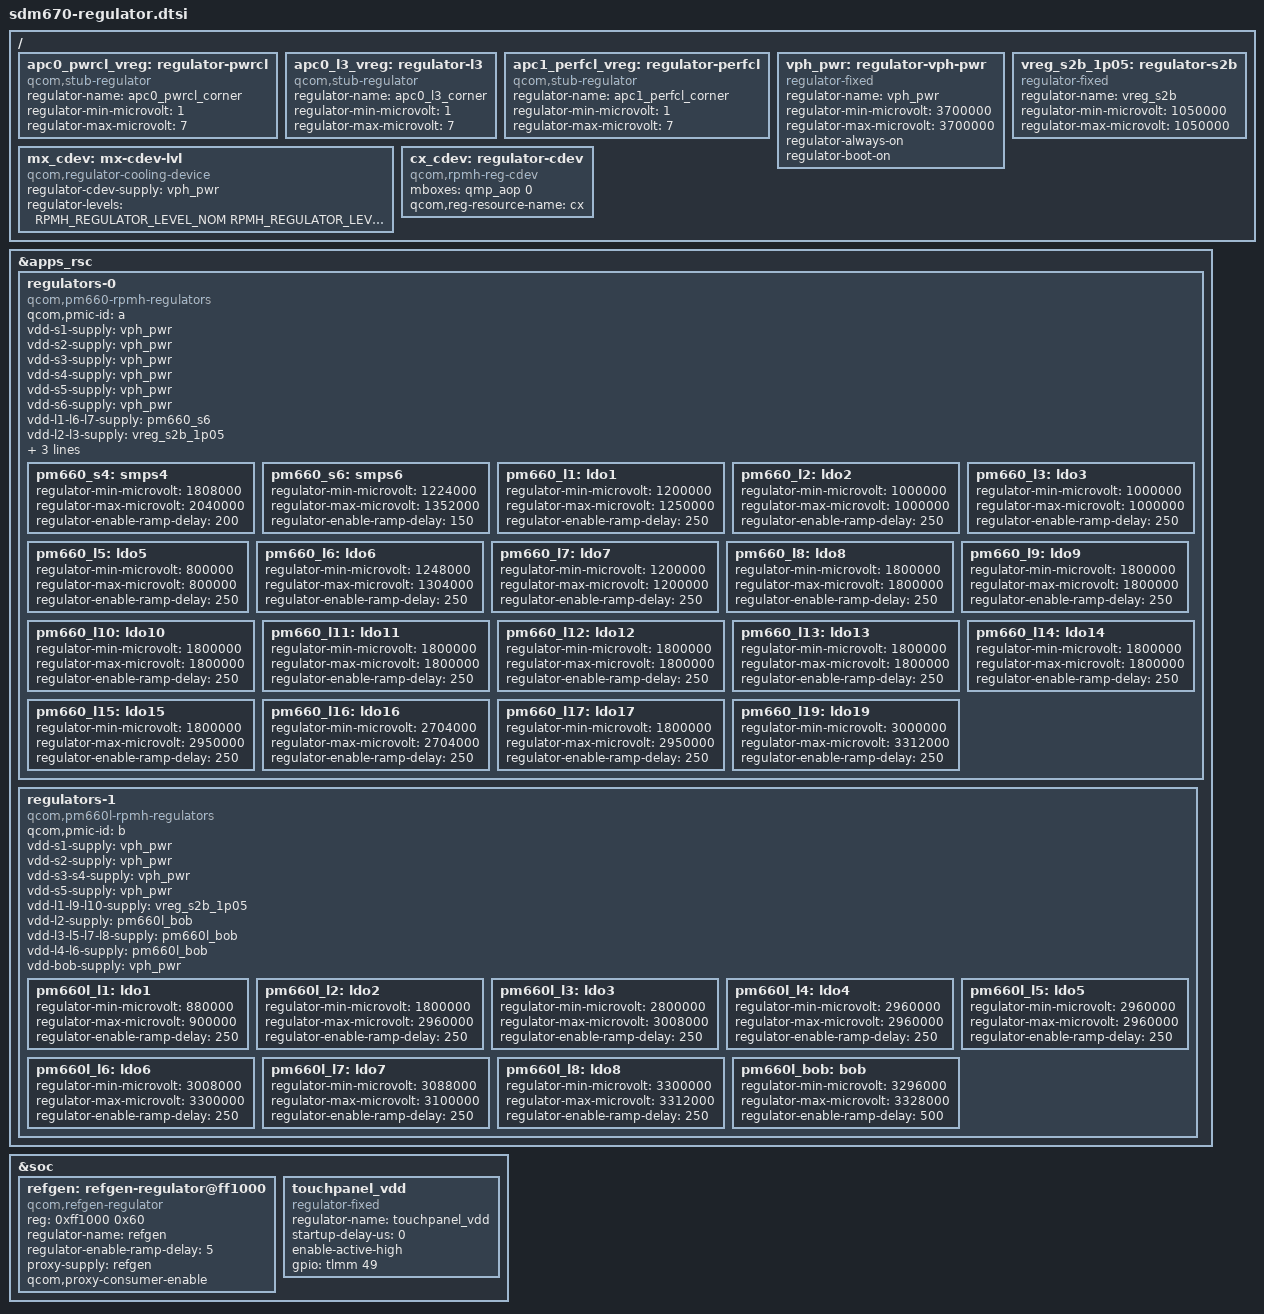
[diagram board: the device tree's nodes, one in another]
/* Copyright (c) 2017,2020 The Linux Foundation. All rights reserved.
 * PBEM00 port: converted from the CLO rpmh-regulator binding (mboxes +
 * qcom,resource-name + ARC level regulators) to the mainline binding
 * (qcom,pm660{,l}-rpmh-regulators under apps_rsc + rpmhpd for ARC rails).
 * All consumer-facing labels (pm660_*, pm660l_*, mx_cdev, cx_cdev) are
 * preserved so the stock dtbo overlay keeps resolving. */

#include <dt-bindings/regulator/qcom,rpmh-regulator.h>

/* Stub regulators */

/ {
	apc0_pwrcl_vreg: regulator-pwrcl {
		compatible = "qcom,stub-regulator";
		regulator-name = "apc0_pwrcl_corner";
		regulator-min-microvolt = <1>;
		regulator-max-microvolt = <7>;
	};

	apc0_l3_vreg: regulator-l3 {
		compatible = "qcom,stub-regulator";
		regulator-name = "apc0_l3_corner";
		regulator-min-microvolt = <1>;
		regulator-max-microvolt = <7>;
	};

	apc1_perfcl_vreg: regulator-perfcl {
		compatible = "qcom,stub-regulator";
		regulator-name = "apc1_perfcl_corner";
		regulator-min-microvolt = <1>;
		regulator-max-microvolt = <7>;
	};

	/* Battery rail feeding the SMPS inputs (cf. sdm670-google-common) */
	vph_pwr: regulator-vph-pwr {
		compatible = "regulator-fixed";
		regulator-name = "vph_pwr";
		regulator-min-microvolt = <3700000>;
		regulator-max-microvolt = <3700000>;
		regulator-always-on;
		regulator-boot-on;
	};

	/* pm660l S2 feed for LDOs (downstream models it as an ARC-only rail;
	 * fixed-voltage placeholder per sdm670-google-common) */
	vreg_s2b_1p05: regulator-s2b {
		compatible = "regulator-fixed";
		regulator-name = "vreg_s2b";
		regulator-min-microvolt = <1050000>;
		regulator-max-microvolt = <1050000>;
	};

	/* Cooling devices (kept label-compatible with sdm670-thermal.dtsi;
	 * the CLO cooling drivers are not present in mainline, so these
	 * merely keep the phandles resolvable) */
	mx_cdev: mx-cdev-lvl {
		compatible = "qcom,regulator-cooling-device";
		regulator-cdev-supply = <&vph_pwr>;
		regulator-levels = <RPMH_REGULATOR_LEVEL_NOM
				RPMH_REGULATOR_LEVEL_OFF>;
		#cooling-cells = <2>;
	};

	cx_cdev: regulator-cdev {
		compatible = "qcom,rpmh-reg-cdev";
		mboxes = <&qmp_aop 0>;
		qcom,reg-resource-name = "cx";
		#cooling-cells = <2>;
	};
};

&apps_rsc {
	regulators-0 {
		compatible = "qcom,pm660-rpmh-regulators";
		qcom,pmic-id = "a";

		vdd-s1-supply = <&vph_pwr>;
		vdd-s2-supply = <&vph_pwr>;
		vdd-s3-supply = <&vph_pwr>;
		vdd-s4-supply = <&vph_pwr>;
		vdd-s5-supply = <&vph_pwr>;
		vdd-s6-supply = <&vph_pwr>;

		vdd-l1-l6-l7-supply = <&pm660_s6>;
		vdd-l2-l3-supply = <&vreg_s2b_1p05>;
		vdd-l5-supply = <&vreg_s2b_1p05>;
		vdd-l8-l9-l10-l11-l12-l13-l14-supply = <&pm660_s4>;
		vdd-l15-l16-l17-l18-l19-supply = <&pm660l_bob>;

		pm660_s4: smps4 {
			regulator-min-microvolt = <1808000>;
			regulator-max-microvolt = <2040000>;
			regulator-enable-ramp-delay = <200>;
		};

		pm660_s6: smps6 {
			regulator-min-microvolt = <1224000>;
			regulator-max-microvolt = <1352000>;
			regulator-enable-ramp-delay = <150>;
		};

		/* LDOs (voltages carried over from the CLO rail table) */
		pm660_l1: ldo1 {
			regulator-min-microvolt = <1200000>;
			regulator-max-microvolt = <1250000>;
			regulator-enable-ramp-delay = <250>;
		};

		pm660_l2: ldo2 {
			regulator-min-microvolt = <1000000>;
			regulator-max-microvolt = <1000000>;
			regulator-enable-ramp-delay = <250>;
		};

		pm660_l3: ldo3 {
			regulator-min-microvolt = <1000000>;
			regulator-max-microvolt = <1000000>;
			regulator-enable-ramp-delay = <250>;
		};

		pm660_l5: ldo5 {
			regulator-min-microvolt = <800000>;
			regulator-max-microvolt = <800000>;
			regulator-enable-ramp-delay = <250>;
		};

		pm660_l6: ldo6 {
			regulator-min-microvolt = <1248000>;
			regulator-max-microvolt = <1304000>;
			regulator-enable-ramp-delay = <250>;
		};

		pm660_l7: ldo7 {
			regulator-min-microvolt = <1200000>;
			regulator-max-microvolt = <1200000>;
			regulator-enable-ramp-delay = <250>;
		};

		pm660_l8: ldo8 {
			regulator-min-microvolt = <1800000>;
			regulator-max-microvolt = <1800000>;
			regulator-enable-ramp-delay = <250>;
		};

		pm660_l9: ldo9 {
			regulator-min-microvolt = <1800000>;
			regulator-max-microvolt = <1800000>;
			regulator-enable-ramp-delay = <250>;
		};

		pm660_l10: ldo10 {
			regulator-min-microvolt = <1800000>;
			regulator-max-microvolt = <1800000>;
			regulator-enable-ramp-delay = <250>;
		};

		pm660_l11: ldo11 {
			regulator-min-microvolt = <1800000>;
			regulator-max-microvolt = <1800000>;
			regulator-enable-ramp-delay = <250>;
		};

		pm660_l12: ldo12 {
			regulator-min-microvolt = <1800000>;
			regulator-max-microvolt = <1800000>;
			regulator-enable-ramp-delay = <250>;
		};

		pm660_l13: ldo13 {
			regulator-min-microvolt = <1800000>;
			regulator-max-microvolt = <1800000>;
			regulator-enable-ramp-delay = <250>;
		};

		pm660_l14: ldo14 {
			regulator-min-microvolt = <1800000>;
			regulator-max-microvolt = <1800000>;
			regulator-enable-ramp-delay = <250>;
		};

		pm660_l15: ldo15 {
			regulator-min-microvolt = <1800000>;
			regulator-max-microvolt = <2950000>;
			regulator-enable-ramp-delay = <250>;
		};

		/* Stock fixes L16 at 2700000; CLO sends raw uV for the firmware to
		 * round, but 2700000 rides between the 8000 uV PMIC4 PLDO steps
		 * (2696000/2704000) and the strict upstream selector mapping
		 * rejects it at register time with -EINVAL, failing the whole
		 * regulators-0 probe. Snap to the ceiling step. */
		pm660_l16: ldo16 {
			regulator-min-microvolt = <2704000>;
			regulator-max-microvolt = <2704000>;
			regulator-enable-ramp-delay = <250>;
		};

		pm660_l17: ldo17 {
			regulator-min-microvolt = <1800000>;
			regulator-max-microvolt = <2950000>;
			regulator-enable-ramp-delay = <250>;
		};

		pm660_l19: ldo19 {
			regulator-min-microvolt = <3000000>;
			regulator-max-microvolt = <3312000>;
			regulator-enable-ramp-delay = <250>;
		};
	};

	regulators-1 {
		compatible = "qcom,pm660l-rpmh-regulators";
		qcom,pmic-id = "b";

		vdd-s1-supply = <&vph_pwr>;
		vdd-s2-supply = <&vph_pwr>;
		vdd-s3-s4-supply = <&vph_pwr>;
		vdd-s5-supply = <&vph_pwr>;

		vdd-l1-l9-l10-supply = <&vreg_s2b_1p05>;
		vdd-l2-supply = <&pm660l_bob>;
		vdd-l3-l5-l7-l8-supply = <&pm660l_bob>;
		vdd-l4-l6-supply = <&pm660l_bob>;
		vdd-bob-supply = <&vph_pwr>;

		/* LDOs (voltages carried over from the CLO rail table) */
		pm660l_l1: ldo1 {
			regulator-min-microvolt = <880000>;
			regulator-max-microvolt = <900000>;
			regulator-enable-ramp-delay = <250>;
		};

		pm660l_l2: ldo2 {
			regulator-min-microvolt = <1800000>;
			regulator-max-microvolt = <2960000>;
			regulator-enable-ramp-delay = <250>;
		};

		pm660l_l3: ldo3 {
			regulator-min-microvolt = <2800000>;
			regulator-max-microvolt = <3008000>;
			regulator-enable-ramp-delay = <250>;
		};

		pm660l_l4: ldo4 {
			regulator-min-microvolt = <2960000>;
			regulator-max-microvolt = <2960000>;
			regulator-enable-ramp-delay = <250>;
		};

		pm660l_l5: ldo5 {
			regulator-min-microvolt = <2960000>;
			regulator-max-microvolt = <2960000>;
			regulator-enable-ramp-delay = <250>;
		};

		pm660l_l6: ldo6 {
			regulator-min-microvolt = <3008000>;
			regulator-max-microvolt = <3300000>;
			regulator-enable-ramp-delay = <250>;
		};

		pm660l_l7: ldo7 {
			regulator-min-microvolt = <3088000>;
			regulator-max-microvolt = <3100000>;
			regulator-enable-ramp-delay = <250>;
		};

		pm660l_l8: ldo8 {
			regulator-min-microvolt = <3300000>;
			regulator-max-microvolt = <3312000>;
			regulator-enable-ramp-delay = <250>;
		};

		/* Downstream fixes BOB at 3.312 V which the PMIC4 BOB ranges
		 * do not support; widen per sdm670-google-common. */
		pm660l_bob: bob {
			regulator-min-microvolt = <3296000>;
			regulator-max-microvolt = <3328000>;
			regulator-enable-ramp-delay = <500>;
		};
	};
};

&soc {
	refgen: refgen-regulator@ff1000 {
		compatible = "qcom,refgen-regulator";
		reg = <0xff1000 0x60>;
		regulator-name = "refgen";
		regulator-enable-ramp-delay = <5>;
		proxy-supply = <&refgen>;
		qcom,proxy-consumer-enable;
	};

	touchpanel_vdd: touchpanel_vdd {
		compatible = "regulator-fixed";
		regulator-name = "touchpanel_vdd";
		startup-delay-us = <0>;
		enable-active-high;
		gpio = <&tlmm 49 0>;
	};
};
